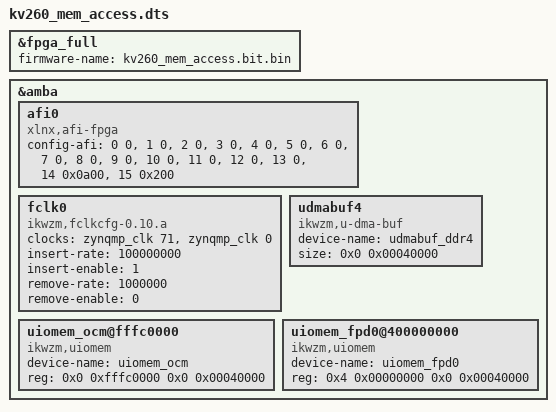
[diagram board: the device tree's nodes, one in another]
/dts-v1/; /plugin/;

/ {
    fragment@0 {
        target = <&fpga_full>;
        overlay0: __overlay__ {
            #address-cells = <2>;
            #size-cells = <2>;
            firmware-name = "kv260_mem_access.bit.bin";
        };
    };
    
    fragment@1 {
        target = <&amba>;
        overlay1: __overlay__ {
            afi0: afi0 {
                compatible = "xlnx,afi-fpga";
                config-afi    = <0  0>,     // S_AXI_HPC0_FPD(read)  : 0:128bit, 1:64bit, 2:32bit
                                <1  0>,     // S_AXI_HPC0_FPD(write) : 0:128bit, 1:64bit, 2:32bit
                                <2  0>,     // S_AXI_HPC1_FPD(read)  : 0:128bit, 1:64bit, 2:32bit
                                <3  0>,     // S_AXI_HPC1_FPD(write) : 0:128bit, 1:64bit, 2:32bit
                                <4  0>,     // S_AXI_HP0_FPD(read)   : 0:128bit, 1:64bit, 2:32bit
                                <5  0>,     // S_AXI_HP0_FPD(write)  : 0:128bit, 1:64bit, 2:32bit
                                <6  0>,     // S_AXI_HP1_FPD(read)   : 0:128bit, 1:64bit, 2:32bit
                                <7  0>,     // S_AXI_HP1_FPD(write)  : 0:128bit, 1:64bit, 2:32bit
                                <8  0>,     // S_AXI_HP2_FPD(read)   : 0:128bit, 1:64bit, 2:32bit
                                <9  0>,     // S_AXI_HP2_FPD(write)  : 0:128bit, 1:64bit, 2:32bit
                                <10 0>,     // S_AXI_HP3_FPD(read)   : 0:128bit, 1:64bit, 2:32bit
                                <11 0>,     // S_AXI_HP3_FPD(write)  : 0:128bit, 1:64bit, 2:32bit
                                <12 0>,     // S_AXI_LPD(read)       : 0:128bit, 1:64bit, 2:32bit
                                <13 0>,     // S_AXI_LPD(write)      : 0:128bit, 1:64bit, 2:32bit
                                <14 0x0a00>,// M_AXI_HPM0_FPD[9:8], M_AXI_HPM0_FPD[11:10] : 0:32bit, 1:64bit, 2:128bit
                                <15 0x200>; // M_AXI_HPM0_LPD        : 0x000:32bit, 0x100:64bit, 0x200:128bit
            };
            /*
            clocking0: clocking0 {
                #clock-cells = <0>;
                assigned-clock-rates = <100000000>;
                assigned-clocks = <&zynqmp_clk 71>;
                clock-output-names = "fabric_clk";
                clocks = <&zynqmp_clk 71>;
                compatible = "xlnx,fclk";
            };
            */
            fclk0  {
                compatible    = "ikwzm,fclkcfg-0.10.a";
                clocks        = <&zynqmp_clk 71 &zynqmp_clk 0>;
                insert-rate   = "100000000";
                insert-enable = <1>;
                remove-rate   = "1000000";
                remove-enable = <0>;
            };
        };
    };

    /*
    fragment@2 {
        target = <&amba>;
        overlay2: __overlay__ {
            #address-cells = <0x2>;
            #size-cells = <0x2>;
            uio_pl_fpd0@a0000000 {
                compatible = "generic-uio";
                reg = <0x0 0xa0000000 0x0 0x10000000>;
            };

            uio_pl_fpd1@b0000000 {
                compatible = "generic-uio";
                reg = <0x0 0xb0000000 0x0 0x10000000>;
            };
            uio_pl_lpd0@c0000000 {
                compatible = "generic-uio";
                reg = <0x0 0xc0000000 0x0 0x20000000>;
            };
            
            uio_ocm@fffc0000 {
                compatible = "generic-uio";
                reg = <0x0 0xfffc0000 0x0 0x00040000>;
            };
        };
    };
    */
    
    fragment@3 {
        target = <&amba>;
        overlay3: __overlay__ {
            #size-cells = <0x2>;
            udmabuf4 {
                compatible = "ikwzm,u-dma-buf";
                device-name = "udmabuf_ddr4";
                size = <0x0 0x00040000>;
            };
        };
    };

    fragment@4 {
        target = <&amba>;
        overlay4: __overlay__ {
            #address-cells = <0x2>;
            #size-cells = <0x2>;

            uiomem_ocm@fffc0000 {
                compatible = "ikwzm,uiomem";
                device-name = "uiomem_ocm";
                reg = <0x0 0xfffc0000 0x0 0x00040000>;
//              sync-offset = <0x00000000>;
//              sync-size = <0x00040000>;
//              sync-direction = <0>;
            };

            uiomem_fpd0@400000000 {
                compatible = "ikwzm,uiomem";
                device-name = "uiomem_fpd0";
                reg = <0x4 0x00000000 0x0 0x00040000>;
//              sync-offset = <0x00000000>;
//              sync-size = <0x00040000>;
//              sync-direction = <0>;
            };
        };
    };
};

